# ESP32C3 register map
File version: 1.0
CPU: RISC-V RV32IMC single-core 1, little endian, no MPU, FPU, 3 interrupt priority bits
Registers are 32-bit, read-write, reset 0x0 unless marked. A register's access mark holds for its fields unless they carry their own. Offsets are from the block's base; [hi:lo] are bit positions; {n}, {i} and the like mark numbered series.

## GDMA
Base 0x6003F000
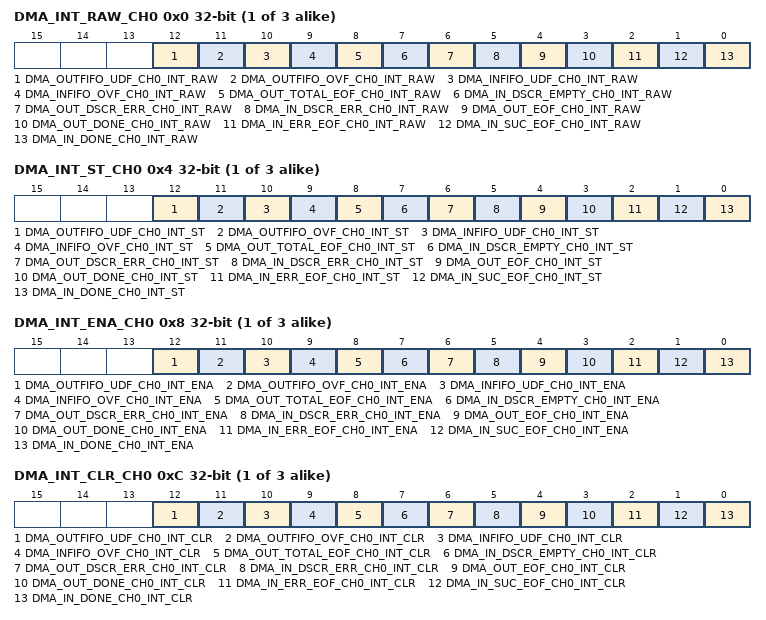
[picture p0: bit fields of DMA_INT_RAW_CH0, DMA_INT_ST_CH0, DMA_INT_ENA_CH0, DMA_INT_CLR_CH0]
{0x0+0x10*i} DMA_INT_RAW_CH{i} (i=0..2)
  [12] DMA_OUTFIFO_UDF_CH{i}_INT_RAW, [11] DMA_OUTFIFO_OVF_CH{i}_INT_RAW, [10] DMA_INFIFO_UDF_CH{i}_INT_RAW, [9] DMA_INFIFO_OVF_CH{i}_INT_RAW, [8] DMA_OUT_TOTAL_EOF_CH{i}_INT_RAW, [7] DMA_IN_DSCR_EMPTY_CH{i}_INT_RAW, [6] DMA_OUT_DSCR_ERR_CH{i}_INT_RAW, [5] DMA_IN_DSCR_ERR_CH{i}_INT_RAW, [4] DMA_OUT_EOF_CH{i}_INT_RAW, [3] DMA_OUT_DONE_CH{i}_INT_RAW, [2] DMA_IN_ERR_EOF_CH{i}_INT_RAW, [1] DMA_IN_SUC_EOF_CH{i}_INT_RAW, [0] DMA_IN_DONE_CH{i}_INT_RAW
{0x4+0x10*i} DMA_INT_ST_CH{i} ro (i=0..2)
  [12] DMA_OUTFIFO_UDF_CH{i}_INT_ST, [11] DMA_OUTFIFO_OVF_CH{i}_INT_ST, [10] DMA_INFIFO_UDF_CH{i}_INT_ST, [9] DMA_INFIFO_OVF_CH{i}_INT_ST, [8] DMA_OUT_TOTAL_EOF_CH{i}_INT_ST, [7] DMA_IN_DSCR_EMPTY_CH{i}_INT_ST, [6] DMA_OUT_DSCR_ERR_CH{i}_INT_ST, [5] DMA_IN_DSCR_ERR_CH{i}_INT_ST, [4] DMA_OUT_EOF_CH{i}_INT_ST, [3] DMA_OUT_DONE_CH{i}_INT_ST, [2] DMA_IN_ERR_EOF_CH{i}_INT_ST, [1] DMA_IN_SUC_EOF_CH{i}_INT_ST, [0] DMA_IN_DONE_CH{i}_INT_ST
{0x8+0x10*i} DMA_INT_ENA_CH{i} (i=0..2)
  [12] DMA_OUTFIFO_UDF_CH{i}_INT_ENA, [11] DMA_OUTFIFO_OVF_CH{i}_INT_ENA, [10] DMA_INFIFO_UDF_CH{i}_INT_ENA, [9] DMA_INFIFO_OVF_CH{i}_INT_ENA, [8] DMA_OUT_TOTAL_EOF_CH{i}_INT_ENA, [7] DMA_IN_DSCR_EMPTY_CH{i}_INT_ENA, [6] DMA_OUT_DSCR_ERR_CH{i}_INT_ENA, [5] DMA_IN_DSCR_ERR_CH{i}_INT_ENA, [4] DMA_OUT_EOF_CH{i}_INT_ENA, [3] DMA_OUT_DONE_CH{i}_INT_ENA, [2] DMA_IN_ERR_EOF_CH{i}_INT_ENA, [1] DMA_IN_SUC_EOF_CH{i}_INT_ENA, [0] DMA_IN_DONE_CH{i}_INT_ENA
{0xC+0x10*i} DMA_INT_CLR_CH{i} wo (i=0..2)
  [12] DMA_OUTFIFO_UDF_CH{i}_INT_CLR, [11] DMA_OUTFIFO_OVF_CH{i}_INT_CLR, [10] DMA_INFIFO_UDF_CH{i}_INT_CLR, [9] DMA_INFIFO_OVF_CH{i}_INT_CLR, [8] DMA_OUT_TOTAL_EOF_CH{i}_INT_CLR, [7] DMA_IN_DSCR_EMPTY_CH{i}_INT_CLR, [6] DMA_OUT_DSCR_ERR_CH{i}_INT_CLR, [5] DMA_IN_DSCR_ERR_CH{i}_INT_CLR, [4] DMA_OUT_EOF_CH{i}_INT_CLR, [3] DMA_OUT_DONE_CH{i}_INT_CLR, [2] DMA_IN_ERR_EOF_CH{i}_INT_CLR, [1] DMA_IN_SUC_EOF_CH{i}_INT_CLR, [0] DMA_IN_DONE_CH{i}_INT_CLR
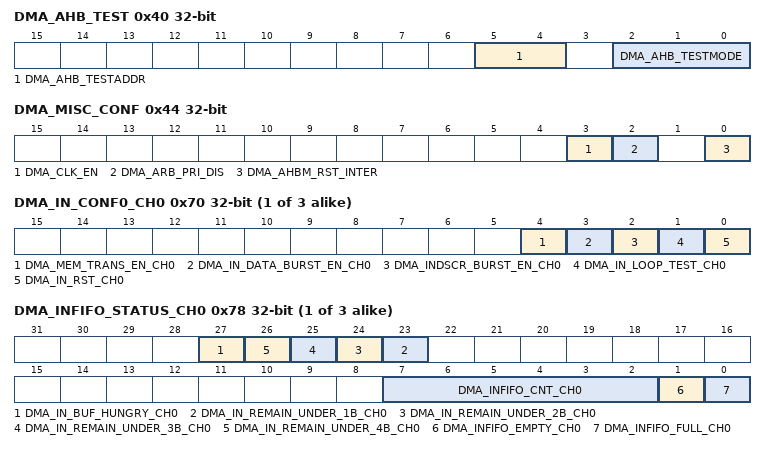
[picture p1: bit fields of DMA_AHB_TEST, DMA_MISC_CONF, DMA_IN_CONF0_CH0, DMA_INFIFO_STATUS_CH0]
0x40 DMA_AHB_TEST
  [5:4] DMA_AHB_TESTADDR, [2:0] DMA_AHB_TESTMODE
0x44 DMA_MISC_CONF
  [3] DMA_CLK_EN, [2] DMA_ARB_PRI_DIS, [0] DMA_AHBM_RST_INTER
0x48 DMA_DATE
{0x70+0xC0*i} DMA_IN_CONF0_CH{i} (i=0..2)
  [4] DMA_MEM_TRANS_EN_CH{i}, [3] DMA_IN_DATA_BURST_EN_CH{i}, [2] DMA_INDSCR_BURST_EN_CH{i}, [1] DMA_IN_LOOP_TEST_CH{i}, [0] DMA_IN_RST_CH{i}
{0x74+0xC0*i} DMA_IN_CONF1_CH{i} (i=0..2)
  [12] DMA_IN_CHECK_OWNER_CH{i}
{0x78+0xC0*i} DMA_INFIFO_STATUS_CH{i} ro (i=0..2)
  [27] DMA_IN_BUF_HUNGRY_CH{i}, [n+22] DMA_IN_REMAIN_UNDER_{n}B_CH{i} (n=1..4), [7:2] DMA_INFIFO_CNT_CH{i}, [1] DMA_INFIFO_EMPTY_CH{i}, [0] DMA_INFIFO_FULL_CH{i}
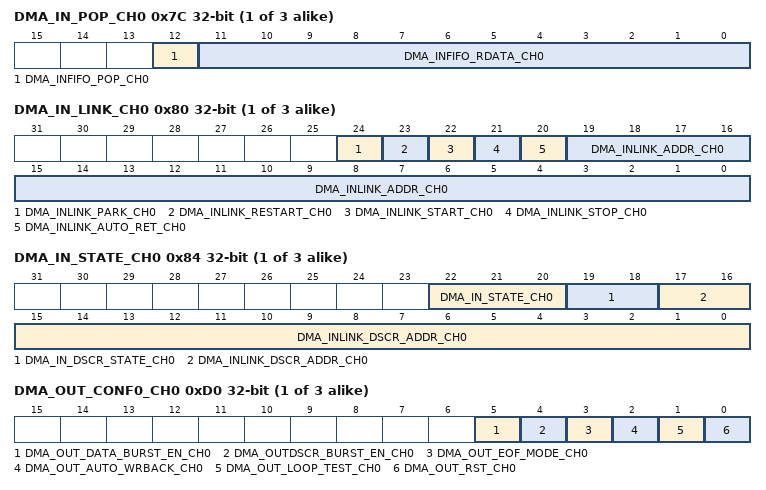
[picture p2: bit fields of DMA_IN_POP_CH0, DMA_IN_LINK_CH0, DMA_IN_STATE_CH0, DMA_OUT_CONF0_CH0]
{0x7C+0xC0*i} DMA_IN_POP_CH{i} access per field (i=0..2)
  [12] DMA_INFIFO_POP_CH{i} rw, [11:0] DMA_INFIFO_RDATA_CH{i} ro
{0x80+0xC0*i} DMA_IN_LINK_CH{i} access per field (i=0..2)
  [24] DMA_INLINK_PARK_CH{i} ro, [23] DMA_INLINK_RESTART_CH{i} rw, [22] DMA_INLINK_START_CH{i} rw, [21] DMA_INLINK_STOP_CH{i} rw, [20] DMA_INLINK_AUTO_RET_CH{i} rw, [19:0] DMA_INLINK_ADDR_CH{i} rw
{0x84+0xC0*i} DMA_IN_STATE_CH{i} ro (i=0..2)
  [22:20] DMA_IN_STATE_CH{i}, [19:18] DMA_IN_DSCR_STATE_CH{i}, [17:0] DMA_INLINK_DSCR_ADDR_CH{i}
{0x88+0xC0*i} DMA_IN_SUC_EOF_DES_ADDR_CH{i} ro (i=0..2)
{0x8C+0xC0*i} DMA_IN_ERR_EOF_DES_ADDR_CH{i} ro (i=0..2)
{0x90+0xC0*i} DMA_IN_DSCR_CH{i} ro (i=0..2)
  [31:0] DMA_INLINK_DSCR_CH{i}
{0x94+0xC0*i} DMA_IN_DSCR_BF0_CH{i} ro (i=0..2)
  [31:0] DMA_INLINK_DSCR_BF0_CH{i}
{0x98+0xC0*i} DMA_IN_DSCR_BF1_CH{i} ro (i=0..2)
  [31:0] DMA_INLINK_DSCR_BF1_CH{i}
{0x9C+0xC0*i} DMA_IN_PRI_CH{i} (i=0..2)
  [3:0] DMA_RX_PRI_CH{i}
{0xA0+0xC0*i} DMA_IN_PERI_SEL_CH{i} (i=0..2)
  [5:0] DMA_PERI_IN_SEL_CH{i}
{0xD0+0xC0*i} DMA_OUT_CONF0_CH{i} (i=0..2)
  [5] DMA_OUT_DATA_BURST_EN_CH{i}, [4] DMA_OUTDSCR_BURST_EN_CH{i}, [3] DMA_OUT_EOF_MODE_CH{i}, [2] DMA_OUT_AUTO_WRBACK_CH{i}, [1] DMA_OUT_LOOP_TEST_CH{i}, [0] DMA_OUT_RST_CH{i}
{0xD4+0xC0*i} DMA_OUT_CONF1_CH{i} (i=0..2)
  [12] DMA_OUT_CHECK_OWNER_CH{i}
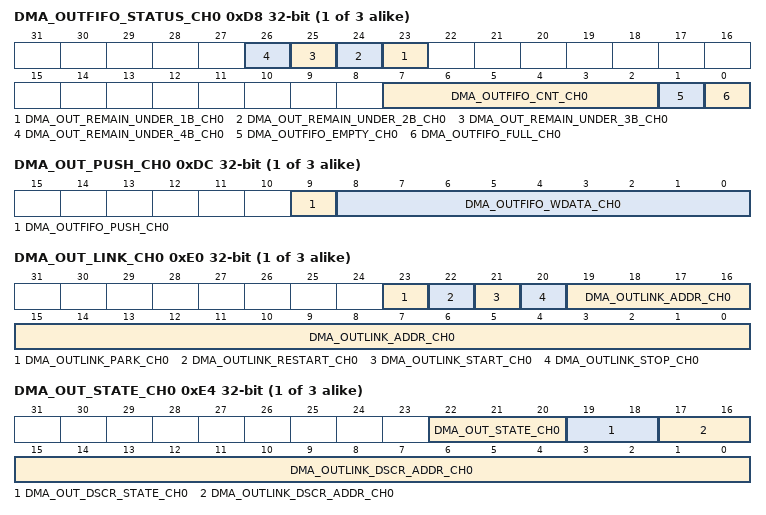
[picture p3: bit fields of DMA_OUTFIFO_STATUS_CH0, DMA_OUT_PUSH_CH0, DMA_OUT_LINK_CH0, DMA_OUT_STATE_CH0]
{0xD8+0xC0*i} DMA_OUTFIFO_STATUS_CH{i} ro (i=0..2)
  [n+22] DMA_OUT_REMAIN_UNDER_{n}B_CH{i} (n=1..4), [7:2] DMA_OUTFIFO_CNT_CH{i}, [1] DMA_OUTFIFO_EMPTY_CH{i}, [0] DMA_OUTFIFO_FULL_CH{i}
{0xDC+0xC0*i} DMA_OUT_PUSH_CH{i} (i=0..2)
  [9] DMA_OUTFIFO_PUSH_CH{i}, [8:0] DMA_OUTFIFO_WDATA_CH{i}
{0xE0+0xC0*i} DMA_OUT_LINK_CH{i} access per field (i=0..2)
  [23] DMA_OUTLINK_PARK_CH{i} ro, [22] DMA_OUTLINK_RESTART_CH{i} rw, [21] DMA_OUTLINK_START_CH{i} rw, [20] DMA_OUTLINK_STOP_CH{i} rw, [19:0] DMA_OUTLINK_ADDR_CH{i} rw
{0xE4+0xC0*i} DMA_OUT_STATE_CH{i} ro (i=0..2)
  [22:20] DMA_OUT_STATE_CH{i}, [19:18] DMA_OUT_DSCR_STATE_CH{i}, [17:0] DMA_OUTLINK_DSCR_ADDR_CH{i}
{0xE8+0xC0*i} DMA_OUT_EOF_DES_ADDR_CH{i} ro (i=0..2)
{0xEC+0xC0*i} DMA_OUT_EOF_BFR_DES_ADDR_CH{i} ro (i=0..2)
{0xF0+0xC0*i} DMA_OUT_DSCR_CH{i} ro (i=0..2)
  [31:0] DMA_OUTLINK_DSCR_CH{i}
{0xF4+0xC0*i} DMA_OUT_DSCR_BF0_CH{i} ro (i=0..2)
  [31:0] DMA_OUTLINK_DSCR_BF0_CH{i}
{0xF8+0xC0*i} DMA_OUT_DSCR_BF1_CH{i} ro (i=0..2)
  [31:0] DMA_OUTLINK_DSCR_BF1_CH{i}
{0xFC+0xC0*i} DMA_OUT_PRI_CH{i} (i=0..2)
  [3:0] DMA_TX_PRI_CH{i}
{0x100+0xC0*i} DMA_OUT_PERI_SEL_CH{i} (i=0..2)
  [5:0] DMA_PERI_OUT_SEL_CH{i}
